# STM32H533 register map
File version: 1.3
CPU: CM33 r0p0, little endian, MPU, FPU, 4 interrupt priority bits
Registers are 32-bit, read-write, reset 0x0 unless marked. A register's access mark holds for its fields unless they carry their own. Offsets are from the block's base; [hi:lo] are bit positions; {n}, {i} and the like mark numbered series; 'fields as' and 'values as' point back to an identical list.

## MPU — Memory Protection Unit -- OPTIONAL on ARMv8-M Mainline (__MPU_PRESENT). Region format changed from ARMv7-M's RBAR/RASR (base + size-encoded) to RBAR/RLAR (base + limit), and gained MAIR0/MAIR1 memory-attribute indirection registers (verified against CMSIS_6 core_cm23.h/core_cm33.h). Includes 3 alias RBAR/RLAR pairs, same as ARMv7-M (MPU_TYPE_RALIASES=4). RLAR.PXN (Privileged eXecute Never, bit 4) is Mainline-only -- absent from Baseline's RLAR entirely, not just RAZ/WI.
Base 0xE000ED90
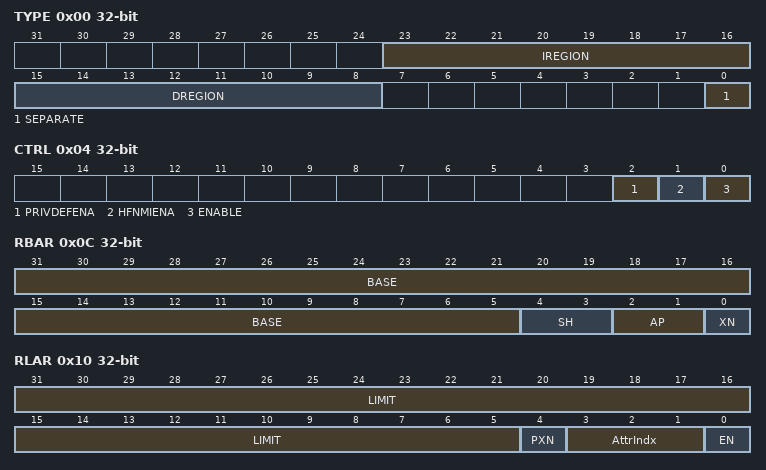
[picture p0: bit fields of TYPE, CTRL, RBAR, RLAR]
0x00 TYPE ro — MPU Type Register
  [23:16] IREGION, [15:8] DREGION, [0] SEPARATE
0x04 CTRL — MPU Control Register
  [2] PRIVDEFENA, [1] HFNMIENA, [0] ENABLE
0x08 RNR — MPU Region Number Register
  [7:0] REGION
0x0C RBAR — MPU Region Base Address Register
  [31:5] BASE — Base address, 32-byte aligned
  [4:3] SH — Shareability
  [2:1] AP — Access permissions
  [0] XN — Execute-never
0x10 RLAR — MPU Region Limit Address Register
  [31:5] LIMIT — Limit address, 32-byte aligned
  [4] PXN — Privileged eXecute Never -- new in CMSIS_6, Mainline only
  [3:1] AttrIndx — MAIR index
  [0] EN — Region enable
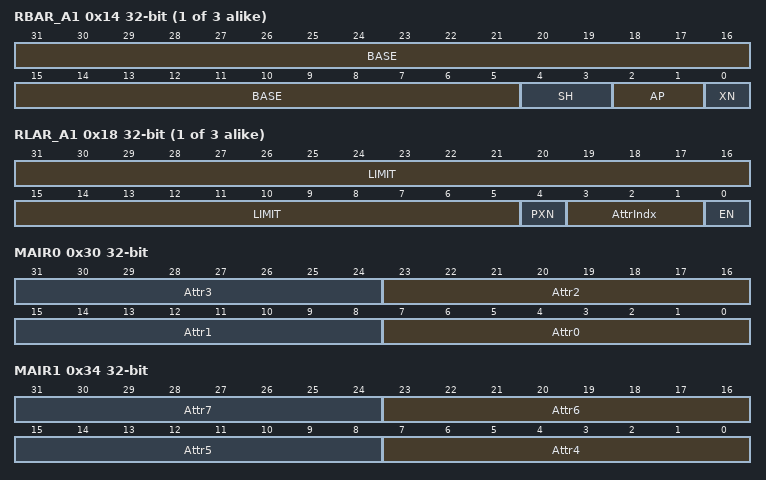
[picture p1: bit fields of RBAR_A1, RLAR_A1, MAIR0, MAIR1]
{0xC+8i} RBAR_A{i} (i=1..3) — MPU Region Base Address Register alias
  fields as RBAR
{0x10+8i} RLAR_A{i} (i=1..3) — MPU Region Limit Address Register alias
  fields as RLAR
0x30 MAIR0 — MPU Memory Attribute Indirection Register 0
  [8n+7:8n] Attr{n} (n=0..3)
0x34 MAIR1 — MPU Memory Attribute Indirection Register 1
  [8n-25:8n-32] Attr{n} (n=4..7)

## NVIC — Nested Vectored Interrupt Controller. ARMv8-M packs interrupt state into 16 banks of 32 bits each (ISER/ICER/ISPR/ICPR/IABR/ITNS) plus 124 32-bit IPR words, covering the full architectural maximum of 496 external interrupts (verified against CMSIS_6 core_cm23.h/core_cm33.h: IPR is a 496-byte array, i.e. 124 words of 4 packed 8-bit priorities each -- same total on both profiles). ITNS (Interrupt Target Non-Secure) is new versus ARMv6-M/ARMv7-M: one bit per interrupt selecting whether it targets the Secure or the Non-secure state; Secure-only access, and RAZ/WI when the Security Extension is not implemented. Mainline additionally has STIR, at the same offset as on ARMv7-M.
Base 0xE000E100
{0x0+4i} ISER{i} (i=0..15) — Interrupt Set-Enable Register
  [31:0] BITS
{0x80+4i} ICER{i} (i=0..15) — Interrupt Clear-Enable Register
  [31:0] BITS
{0x100+4i} ISPR{i} (i=0..15) — Interrupt Set-Pending Register
  [31:0] BITS
{0x180+4i} ICPR{i} (i=0..15) — Interrupt Clear-Pending Register
  [31:0] BITS
{0x200+4i} IABR{i} (i=0..15) ro — Interrupt Active Bit Register
  [31:0] BITS
{0x280+4i} ITNS{i} (i=0..15) — Interrupt Target Non-Secure Register -- Security Extension only, Secure-accessible
  [31:0] BITS
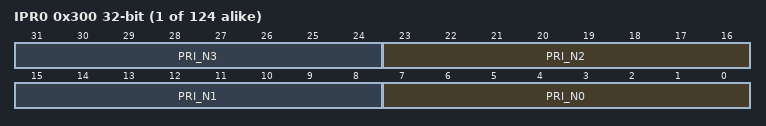
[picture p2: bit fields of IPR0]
{0x300+4i} IPR{i} (i=0..123) — Interrupt Priority Registers 0-123 (cover IRQ0..IRQ495)
  [8n+7:8n] PRI_N{n} (n=0..3) — Priority, byte offset {n}
0xE00 STIR wo — Software Trigger Interrupt Register. Only usable if SCB->CCR.USERSETMPEND allows unprivileged access and the device implements this register.
  [8:0] INTID — Interrupt ID of the interrupt to trigger, 0-495

## PKA — PKA register blank and RAM
Base 0x420C2000
Same registers: PKA_S 0x520C2000
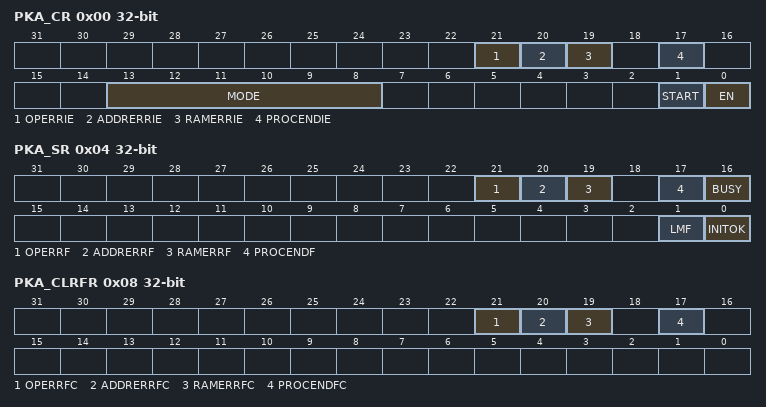
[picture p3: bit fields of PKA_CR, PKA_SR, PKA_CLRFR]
0x00 PKA_CR — PKA control register
  [21] OPERRIE — Operation error interrupt enable
    0=No interrupt is generated when OPERRF flag is set in PKA_SR; 1=An interrupt is generated when OPERRF flag is set in PKA_SR
  [20] ADDRERRIE — Address error interrupt enable
    0=No interrupt is generated when ADDRERRF flag is set in PKA_SR; 1=An interrupt is generated when ADDRERRF flag is set in PKA_SR
  [19] RAMERRIE — RAM error interrupt enable
    0=No interrupt is generated when RAMERRF flag is set in PKA_SR; 1=An interrupt is generated when RAMERRF flag is set in PKA_SR
  [17] PROCENDIE — End of operation interrupt enable
    0=No interrupt is generated when PROCENDF flag is set in PKA_SR; 1=An interrupt is generated when PROCENDF flag is set in PKA_SR
  [13:8] MODE — PKA operation code
    0=Montgomery parameter computation then modular exponentiation; 1=Montgomery parameter computation only; 2=Modular exponentiation only (Montgomery parameter must be loaded first); 3=Modular exponentiation (protected, used when manipulating secrets); 32=Montgomery parameter computation then ECC scalar multiplication (protected); 36=ECDSA sign (protected); 38=ECDSA verification; 40=Point on elliptic curve Fp check; 7=RSA CRT exponentiation; 8=Modular inversion; 9=Arithmetic addition; 10=Arithmetic subtraction; 11=Arithmetic multiplication; 12=Arithmetic comparison; 13=Modular reduction; 14=Modular addition; 15=Modular subtraction; 16=Montgomery multiplication; 35=ECC complete addition; 39=ECC double base ladder; 47=ECC projective to affine
  [1] START — start the operation
  [0] EN — PKA enable
    0=Disable PKA; 1=Enable PKA
0x04 PKA_SR ro — PKA status register
  [21] OPERRF — Operation error flag
    0=No event error; 1=An illegal or unknown operation has been selected in PKA_CR register
  [20] ADDRERRF — Address error flag
    0=No address error; 1=Address access is out of range (unmapped address)
  [19] RAMERRF — PKA RAM error flag
    0=No PKA RAM access error; 1=An AHB access to the PKA RAM occurred while the PKA core was computing and using its internal RAM (AHB PKA_RAM access are not allowed while PKA operation is in progress)
  [17] PROCENDF — PKA end of operation flag
    0=Operation in progress; 1=PKA operation is completed
  [16] BUSY — Busy flag
    0=No operation is in progress (default); 1=An operation is in progress
  [1] LMF — Limited mode flag
    0=All values documented in MODE bitfield can be used; 1=Only ECDSA verification (MODE = 0x26) is supported by the PKA
  [0] INITOK — PKA initialization OK
    0=PKA is not initialized correctly; 1=PKA is initialized correctly and can be used normally
0x08 PKA_CLRFR wo — PKA clear flag register
  [21] OPERRFC — Clear operation error flag
    0=No action; 1=Clear the OPERRF flag in PKA_SR
  [20] ADDRERRFC — Clear address error flag
    0=No action; 1=Clear the ADDRERRF flag in PKA_SR
  [19] RAMERRFC — Clear PKA RAM error flag
    0=No action; 1=Clear the RAMERRF flag in PKA_SR
  [17] PROCENDFC — Clear PKA end of operation flag
    0=No action; 1=Clear the PROCENDF flag in PKA_SR
